# ESP32S31_RADIO register map
Vendor: Espressif; Series: ESP32-S31; File version: 3.52
Registers are 32-bit, read-write, no defined reset value unless marked. A register's access mark holds for its fields unless they carry their own. Offsets are from the block's base; [hi:lo] are bit positions; {n}, {i} and the like mark numbered series; <NAME> marks a mode.

## FROM_CPU_0 — Software interrupt line 0 (interrupt source FROM_CPU_INTR0): one level bit a store of one raises and a store of zero lowers. Wakers raise it from every context and the line's handler lowers it, so it is a shared block whose one register is stored whole.
Base 0x20586010
0x00 LINE reset 0x0 — Project-assigned name. The level of software interrupt line 0.
  [0] RAISED — Project-assigned name. One raises the line's interrupt; zero lowers it.

## FROM_CPU_1 — Software interrupt line 1 (interrupt source FROM_CPU_INTR1): one level bit a store of one raises and a store of zero lowers. Wakers raise it from every context and the line's handler lowers it, so it is a shared block whose one register is stored whole.
Base 0x20586014
0x00 LINE reset 0x0 — Project-assigned name. The level of software interrupt line 1.
  [0] RAISED — Project-assigned name. One raises the line's interrupt; zero lowers it.

## FROM_CPU_2 — Software interrupt line 2 (interrupt source FROM_CPU_INTR2): one level bit a store of one raises and a store of zero lowers. Wakers raise it from every context and the line's handler lowers it, so it is a shared block whose one register is stored whole.
Base 0x20586018
0x00 LINE reset 0x0 — Project-assigned name. The level of software interrupt line 2.
  [0] RAISED — Project-assigned name. One raises the line's interrupt; zero lowers it.

## FROM_CPU_3 — Software interrupt line 3 (interrupt source FROM_CPU_INTR3): one level bit a store of one raises and a store of zero lowers. Wakers raise it from every context and the line's handler lowers it, so it is a shared block whose one register is stored whole.
Base 0x2058601C
0x00 LINE reset 0x0 — Project-assigned name. The level of software interrupt line 3.
  [0] RAISED — Project-assigned name. One raises the line's interrupt; zero lowers it.

## CLIC — The core-local interrupt controller of the hart that accesses it, as 32-bit words: each line's word holds its pending, enable, attribute and control bytes. Invariant: every vectored line is level-triggered, so a write of the word that changes its enable or control writes back the pending bit read without losing or inventing an interrupt (SOURCE: ESP_HAL_1F646C5_CLIC_LEVEL_LINES). INT_CONFIG holds the number of level bits of each line's control byte.
Base 0x10800000
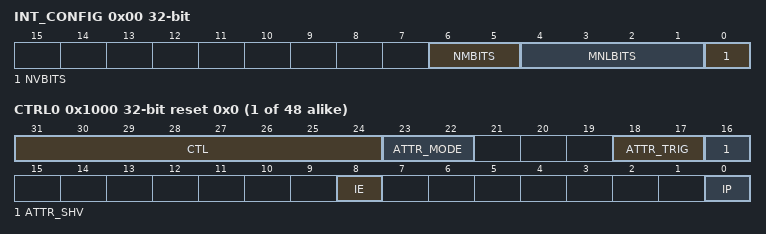
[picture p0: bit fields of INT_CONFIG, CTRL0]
0x00 INT_CONFIG — Project-assigned name. The controller's configuration: how many bits of a line's control byte are its level.
  [6:5] NMBITS ro — Project-assigned name. The number of privilege-mode bits of a line's attribute.
  [4:1] MNLBITS — Project-assigned name. Machine mode: the number of high bits of a line's control byte that are its level, at most 8.
  [0] NVBITS ro — Project-assigned name. Set: the controller implements hardware vectoring.
{0x1000+4i} CTRL{i} (i=0..47) reset 0x0 — Project-assigned name. Line {i}: pending, enable, attribute and level control.
  [31:24] CTL — Project-assigned name. Level and priority control; with three level bits a level-n line holds 0x1f | (n - 1) << 5.
  [23:22] ATTR_MODE — Project-assigned name. Privilege mode of the line.
  [18:17] ATTR_TRIG — Project-assigned name. Trigger: bit 0 clear is level, set is edge; bit 1 selects the negative polarity.
  [16] ATTR_SHV — Project-assigned name. Selects hardware vectoring for the line.
  [8] IE — Project-assigned name. Enables the line.
  [0] IP — Project-assigned name. The line's pending bit; for a level-triggered line it follows the source.

## INTERRUPT_CORE0 — The interrupt-matrix route words of core 0, one per peripheral source, by source number, ZB_MAC (source 132) included.
Base 0x20585000
Same registers: INTERRUPT_CORE1 0x20585800
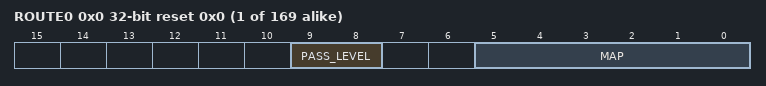
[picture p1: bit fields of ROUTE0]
{0x0+4i} ROUTE{i} (i=0..168) reset 0x0 — Project-assigned name. Route of source {i}.
  [9:8] PASS_LEVEL — Project-assigned name. Remap level of the source: zero none, one S-level, two or three M-level.
  [5:0] MAP — Project-assigned name. The CPU interrupt line the source is routed to; zero routes it nowhere.

## INTERRUPT_CORE0_STATUS — The pending state of every peripheral source at core 0's interrupt matrix. Every context polls it, so it is a shared block of side-effect-free reads.
Base 0x205852A8
Same registers: INTERRUPT_CORE1_STATUS 0x20585AA8
{0x0+4i} INT_STATUS_{i} ro reset 0x0 (i=0..4) — Project-assigned name. Pending state of sources {32i} to {32i+31}, one bit each.
  [31:0] SOURCES — Project-assigned name. Bit k is set while source {32i} + k raises its interrupt.
0x14 INT_STATUS_5 ro reset 0x0 — Project-assigned name. Pending state of sources 160 to 168, one bit each.
  [8:0] SOURCES — Project-assigned name. Bit k is set while source 160 + k raises its interrupt.

## WIFI_MAC_INTERFACE_ADDRESS — Four interface-address pairs consumed by MAC receive filtering.
Base 0x2010405C
{0x0+8i} ADDRESS_LOW{i} (i=0..3) — Project-assigned name. Interface MAC bytes 0..3 in little-endian order, published by the first full-word store.
  [31:0] BYTES_0_3 — Project-assigned name.
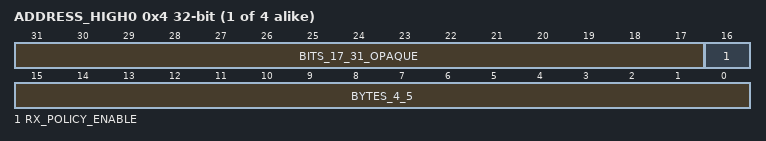
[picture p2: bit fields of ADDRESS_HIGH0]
{0x4+8i} ADDRESS_HIGH{i} (i=0..3) — Project-assigned name. Interface MAC bytes 4..5 are published as a full-word store before a separate fresh-read RMW sets receive-policy enable bit 16.
  [31:17] BITS_17_31_OPAQUE — Opaque: meaning not established.
  [16] RX_POLICY_ENABLE — Project-assigned name. Set by a separate fresh-read RMW in hal_mac_set_addr and by the reachable associated-STA policy branch.
  [15:0] BYTES_4_5 — Project-assigned name.
